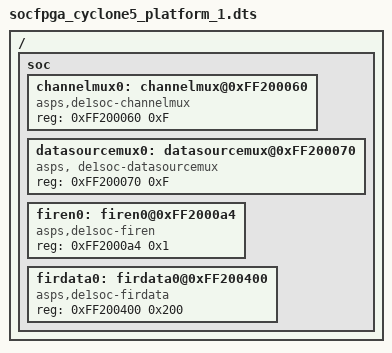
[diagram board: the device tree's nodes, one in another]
/*
 * Copyright (C) 2017 Johannes Posch <johannes.posch@students.fh-hagenberg.at>
 *
 * The code contained herein is licensed under the GNU General Public
 * License. You may obtain a copy of the GNU General Public License
 * Version 2 or later at the following locations:
 *
 * http://www.opensource.org/licenses/gpl-license.html
 * http://www.gnu.org/copyleft/gpl.html
 */

/*
 * The system runs on a cyclon5 FPGA. Thus, we need to include the DE1-SoC DTS.
 */
#include "socfpga_cyclone5_de1soc.dts"

/ {
	soc {
		channelmux0: channelmux@0xFF200060 {
			compatible = "asps,de1soc-channelmux";
			reg = <0xFF200060 0xF>;
		};

		datasourcemux0: datasourcemux@0xFF200070 {
			compatible = "asps, de1soc-datasourcemux";
			reg = <0xFF200070 0xF>;
		};

		firen0: firen0@0xFF2000a4 {
			compatible = "asps,de1soc-firen";
			reg = <0xFF2000a4 0x1>;
		};

		firdata0: firdata0@0xFF200400 {
			compatible = "asps,de1soc-firdata";
			reg = <0xFF200400 0x200>;
		};
	};
};
